AUTOSAR XML (schema 4-3-0)
package /ComponentTypes
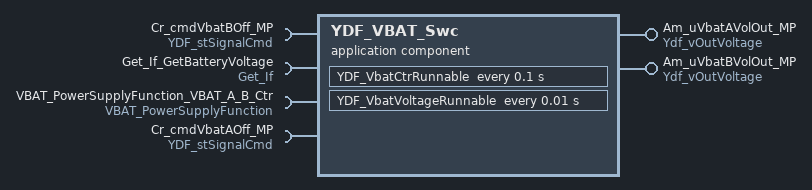
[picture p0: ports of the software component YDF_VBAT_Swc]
  application sw component type YDF_VBAT_Swc
    provide port Am_uVbatAVolOut_MP: nonqueued-sender-com-spec{data-element=OutVoltage, init-value=0}, provided-interface=Ydf_vOutVoltage
    require port Cr_cmdVbatBOff_MP: nonqueued-receiver-com-spec{data-element=SignalCmd, init-value=0}, required-interface=YDF_stSignalCmd
    require port Get_If_GetBatteryVoltage: required-interface=Get_If
      required-com-specs:
        Get_Ad_Result
        Get_io_inResult
        Get_BTS_OutResult
        Get_CAN_ActiveInf
        Icu_17_GtmCcu6_PWMIN_CH{1..4}
        Icu_17_GtmCcu6_PWMIN_PWMSCB1
        Icu_17_GtmCcu6_PWMIN_PWMSCB2
        Icu_17_GtmCcu6_PWMIN_LAMPSCB1
        Icu_17_GtmCcu6_PWMIN_LAMPSCB2
        Get_Bottom_Ver
        Get_SentData
        Get_Level_OutResult
        Get_PwmOrLevel_OutResult
        Get_Motor_OutResult
    require port VBAT_PowerSupplyFunction_VBAT_A_B_Ctr: required-com-specs=[D_VBAT_A_OFF, D_VBAT_B_OFF], required-interface=VBAT_PowerSupplyFunction
    provide port Am_uVbatBVolOut_MP: nonqueued-sender-com-spec{data-element=OutVoltage, init-value=0}, provided-interface=Ydf_vOutVoltage
    require port Cr_cmdVbatAOff_MP: nonqueued-receiver-com-spec{data-element=SignalCmd, init-value=0}, required-interface=YDF_stSignalCmd
    behavior YDF_VBAT_Swc_InternalBehavior
      timing event TMT_YDF_VbatCtrRunnable: start-on-event=YDF_VbatCtrRunnable, period=0.1
      timing event TMT_YDF_VbatVoltageRunnable: start-on-event=YDF_VbatVoltageRunnable, period=0.01
      runnable YDF_VbatCtrRunnable
        data-receive-point-by-arguments:
          access REC_Cr_cmdVbatAOff_MP_SignalCmd: accessed-variable=Cr_cmdVbatBOff_MP.SignalCmd
          access REC_Cr_cmdVbatAOff_MP_SignalCmd_1: accessed-variable=Cr_cmdVbatAOff_MP.SignalCmd
        sync call SC_VBAT_PowerSupplyFunction_VBAT_A_B_Ctr_D_VBAT_A_OFF: operation=VBAT_PowerSupplyFunction_VBAT_A_B_Ctr.D_VBAT_A_OFF
        sync call SC_VBAT_PowerSupplyFunction_VBAT_A_B_Ctr_D_VBAT_B_OFF: operation=VBAT_PowerSupplyFunction_VBAT_A_B_Ctr.D_VBAT_B_OFF
      runnable YDF_VbatVoltageRunnable
        data-send-points:
          access SEND_Am_uVbatAVolOut_MP_OutVoltage: accessed-variable=Am_uVbatAVolOut_MP.OutVoltage
          access SEND_Am_uVbatBVolOut_MP_OutVoltage: accessed-variable=Am_uVbatBVolOut_MP.OutVoltage
        sync call SC_Get_If_GetBatteryVoltage_Get_Ad_Result: operation=Get_If_GetBatteryVoltage.Get_Ad_Result
  swc implementation YDF_VBAT_Swc_Implementation: behavior=YDF_VBAT_Swc_InternalBehavior
